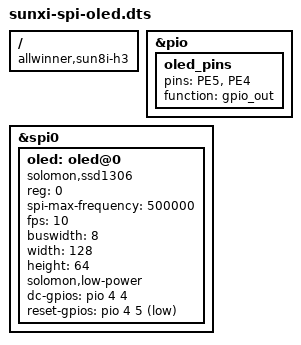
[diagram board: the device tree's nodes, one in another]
/dts-v1/;
/plugin/;

/ {
  compatible = "allwinner,sun8i-h3", "allwinner,sun8i-a83t", "allwinner,sun50i-a64", "allwinner,sun50i-h5";

  fragment@0 {
    target = <&pio>;
    __overlay__ {
      oled_pins: oled_pins {
        pins = "PE5", "PE4";
        function = "gpio_out";
      };
    };
  };

  fragment@1 {
    target = <&spi0>;

    __overlay__ {
      #address-cells = <1>;
      #size-cells = <0>;

			status = "okay";

      oled: oled@0 {
        compatible = "solomon,ssd1306";
        reg = <0>;

        spi-max-frequency = <500000>;
        fps = <10>;
        buswidth = <8>;

        width = <128>;
        height = <64>;
        
        solomon,low-power;

        dc-gpios = <&pio 4 4 0>;
        reset-gpios = <&pio 4 5 1>;
      };
    };
  };


};
